AUTOSAR XML (schema 4-0-3)
package /ComponentTypes
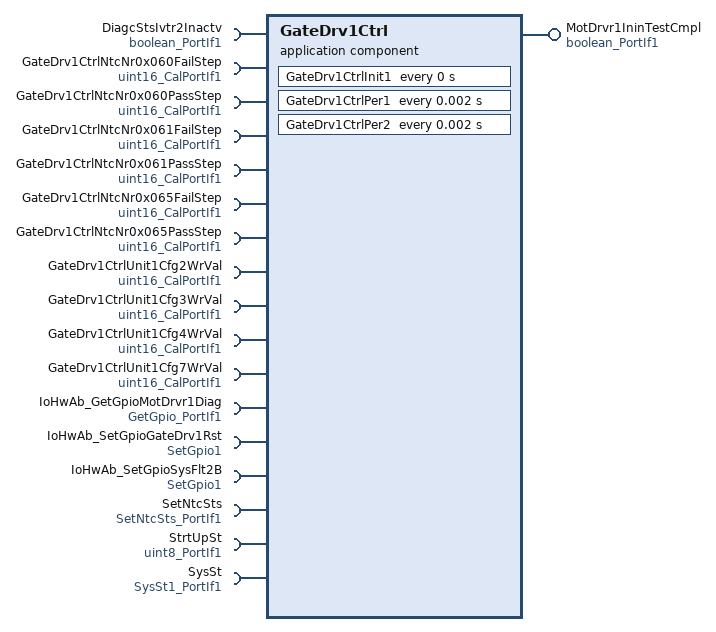
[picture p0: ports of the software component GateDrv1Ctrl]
  application sw component type GateDrv1Ctrl
    provide port MotDrvr1IninTestCmpl: nonqueued-sender-com-spec{data-element=Logl, init-value=0}, provided-interface=boolean_PortIf1
    17 x require port:
      DiagcStsIvtr2Inactv: nonqueued-receiver-com-spec{data-element=Logl, filter=data-filter-type=ALWAYS, init-value=0}, required-interface=boolean_PortIf1
      GateDrv1CtrlNtcNr0x060FailStep: parameter-require-com-spec{init-value=4096, parameter=Val}, required-interface=uint16_CalPortIf1
      GateDrv1CtrlNtcNr0x060PassStep: parameter-require-com-spec{init-value=4096, parameter=Val}, required-interface=uint16_CalPortIf1
      GateDrv1CtrlNtcNr0x061FailStep: parameter-require-com-spec{init-value=4096, parameter=Val}, required-interface=uint16_CalPortIf1
      GateDrv1CtrlNtcNr0x061PassStep: parameter-require-com-spec{init-value=4096, parameter=Val}, required-interface=uint16_CalPortIf1
      GateDrv1CtrlNtcNr0x065FailStep: parameter-require-com-spec{init-value=4096, parameter=Val}, required-interface=uint16_CalPortIf1
      GateDrv1CtrlNtcNr0x065PassStep: parameter-require-com-spec{init-value=4096, parameter=Val}, required-interface=uint16_CalPortIf1
      GateDrv1CtrlUnit1Cfg2WrVal: parameter-require-com-spec{init-value=2832, parameter=Val}, required-interface=uint16_CalPortIf1
      GateDrv1CtrlUnit1Cfg3WrVal: parameter-require-com-spec{init-value=3598, parameter=Val}, required-interface=uint16_CalPortIf1
      GateDrv1CtrlUnit1Cfg4WrVal: parameter-require-com-spec{init-value=4622, parameter=Val}, required-interface=uint16_CalPortIf1
      GateDrv1CtrlUnit1Cfg7WrVal: parameter-require-com-spec{init-value=7924, parameter=Val}, required-interface=uint16_CalPortIf1
      IoHwAb_GetGpioMotDrvr1Diag: required-interface=GetGpio_PortIf1
      IoHwAb_SetGpioGateDrv1Rst: required-interface=SetGpio1
      IoHwAb_SetGpioSysFlt2B: required-interface=SetGpio1
      SetNtcSts: required-interface=SetNtcSts_PortIf1
      StrtUpSt: nonqueued-receiver-com-spec{data-element=Val, filter=data-filter-type=ALWAYS, init-value=0}, required-interface=uint8_PortIf1
      SysSt: nonqueued-receiver-com-spec{data-element=Val, filter=data-filter-type=ALWAYS, init-value=3}, required-interface=SysSt1_PortIf1
    behavior GateDrv1Ctrl_InternalBehavior
      ar-typed-per-instance-memorys:
        22 x data, all with sw-calibration-access=READ-ONLY:
          dGateDrv1CtrlGateDrv1Diag{0..2}Val: type=uint16
          dGateDrv1CtrlGateDrv1OffsStVrfyPrmBitIdx: type=uint8
          dGateDrv1CtrlGateDrv1StsVal: type=uint16
          dGateDrv1CtrlGateDrv1VrfyRes0Val: type=uint16
          dGateDrv1CtrlGateDrv1VrfyRes1Val: type=uint16
          GateDrv1CfgCnt: type=uint8
          GateDrv1CfgSecAtmpt: type=boolean
          GateDrv1Diag{0..2}Val: type=uint16
          GateDrv1OffStChkIdx: type=uint8
          GateDrv1OffStChkSecAtmpt: type=boolean
          GateDrv1OffStCnt: type=uint8
          GateDrv1St: type=uint8
          GateDrv1StsVal: type=uint16
          GateDrv1VrfyRes0Val: type=uint16
          GateDrv1VrfyRes1Val: type=uint16
          Ivtr1BootstrpSplyFltPrmVal: type=uint8
          Ivtr1GenericFltPrmVal: type=uint8
          Ivtr1OffStChkCmpl: type=boolean
      timing event GateDrvCtrl_InitEvent: start-on-event=GateDrv1CtrlInit1, period=0
      timing event TMT_GateDrvCtrlPer1: start-on-event=GateDrv1CtrlPer1, period=0.002
      timing event TMT_GateDrv0CtrlPer2: start-on-event=GateDrv1CtrlPer2, period=0.002
      explicit-inter-runnable-variables:
        data GateDrv1Ena: type=boolean, init-value=0
        data Ivtr1PhyFltInpActv: type=boolean, init-value=0
      runnable GateDrv1CtrlInit1
      runnable GateDrv1CtrlPer1
        data-receive-point-by-arguments:
          access REC_DiagcStsIvtr1Inactv_Logl: accessed-variable=DiagcStsIvtr2Inactv.Logl
          access REC_StrtUpSt_Val: accessed-variable=StrtUpSt.Val
          access REC_SysSt_Val: accessed-variable=SysSt.Val
        sync call SC_IoHwAb_GetGpioMotDrvr0Diag_Oper: operation=IoHwAb_GetGpioMotDrvr1Diag.Oper, timeout=0
        sync call SC_IoHwAb_SetGpioGateDrv0Rst_Oper: operation=IoHwAb_SetGpioGateDrv1Rst.Oper, timeout=0
        written-local-variables:
          access WRITE_GateDrv1Ena: accessed-variable=GateDrv1Ena
          access WRITE_Ivtr1PhyFltInpActv: accessed-variable=Ivtr1PhyFltInpActv
      runnable GateDrv1CtrlPer2
        data-receive-point-by-arguments:
          access REC_DiagcStsIvtr1Inactv_Logl: accessed-variable=DiagcStsIvtr2Inactv.Logl
        data-send-points:
          access SEND_MotDrvr0IninTestCmpl_Logl: accessed-variable=MotDrvr1IninTestCmpl.Logl
        read-local-variables:
          access READ_GateDrv1Ena: accessed-variable=GateDrv1Ena
          access READ_Ivtr1PhyFltInpActv: accessed-variable=Ivtr1PhyFltInpActv
        4 x sync call, all with timeout=0:
          SC_IoHwAb_GetGpioMotDrvr0Diag_Oper: operation=IoHwAb_GetGpioMotDrvr1Diag.Oper
          SC_IoHwAb_SetGpioGateDrv0Rst_Oper: operation=IoHwAb_SetGpioGateDrv1Rst.Oper
          SC_IoHwAb_SetGpioSysFlt2A_Oper: operation=IoHwAb_SetGpioSysFlt2B.Oper
          SC_SetNtcSts_Oper: operation=SetNtcSts.Oper
  swc implementation GateDrv1Ctrl_Implementation: behavior=GateDrv1Ctrl_InternalBehavior
    code-descriptors:
      code Default: artifact-descriptors=autosar-engineering-object={short-label=Default, category=SWSRC}
